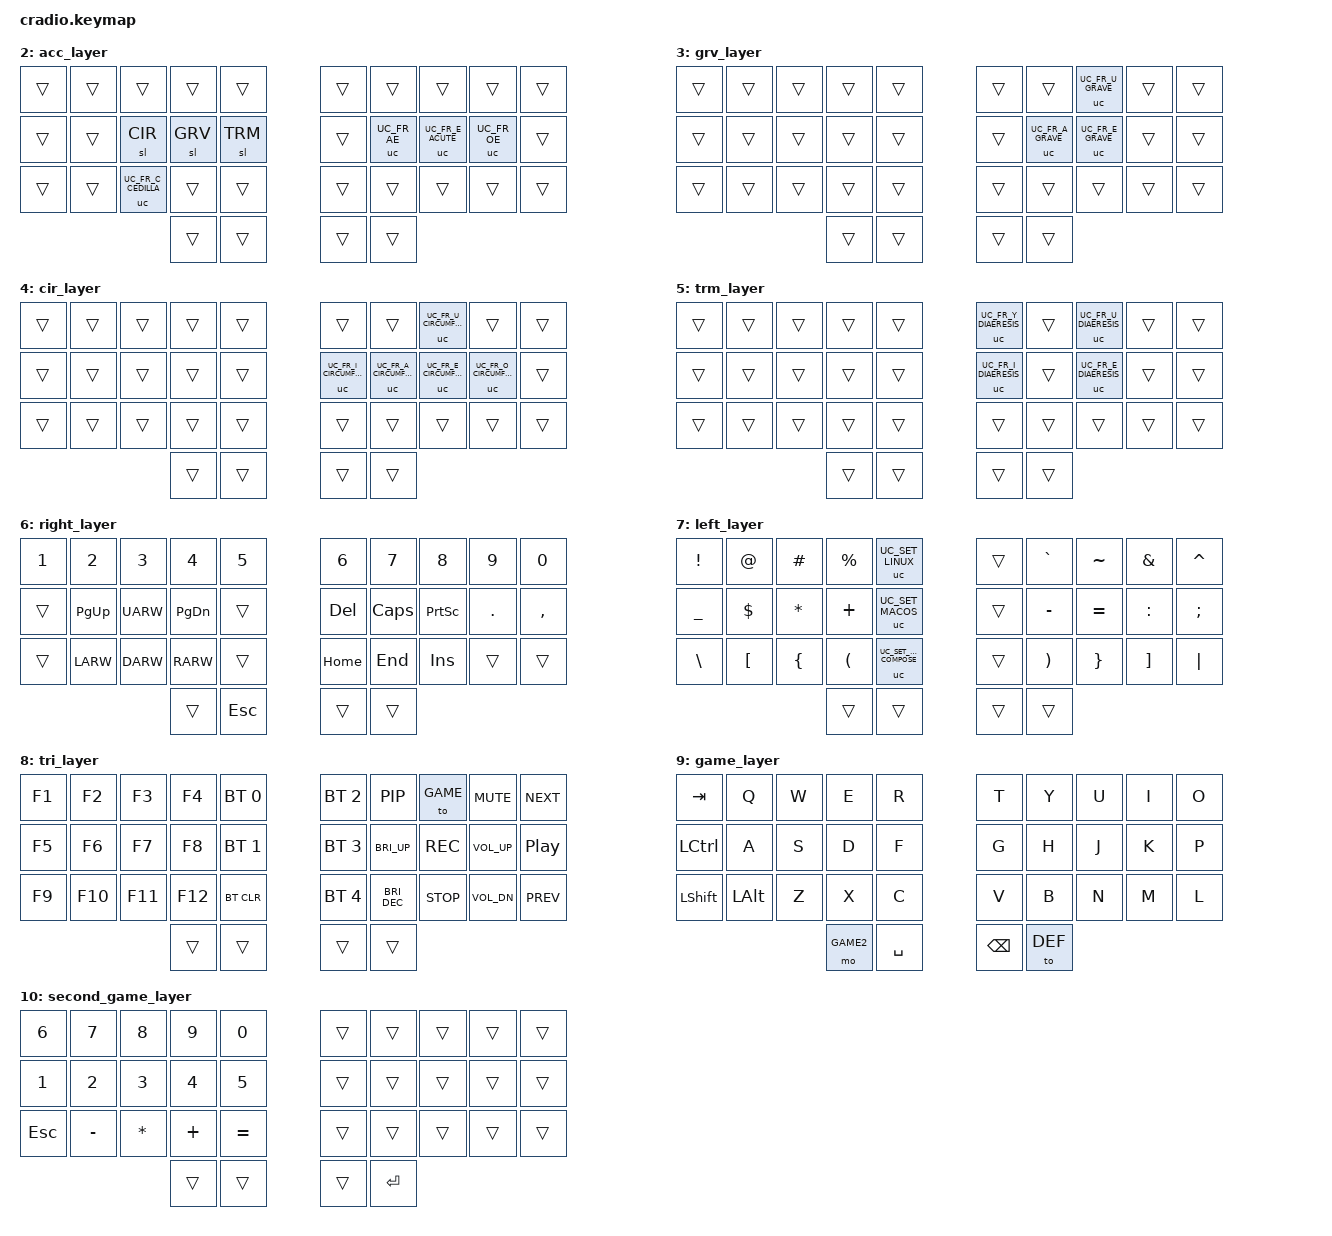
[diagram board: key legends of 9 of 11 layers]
// Copyright (c) 2022 The ZMK Contributors
// SPDX-License-Identifier: MIT

//template
        //╭──────────┬──────────┬──────────┬──────────┬──────────╮   ╭──────────┬──────────┬──────────┬──────────┬──────────╮
        //│          │          │          │          │          │   │          │          │          │          │          │
        // &trans     &trans     &trans     &trans     &trans         &trans     &trans     &trans     &trans      &trans
        //├──────────┼──────────┼──────────┼──────────┼──────────┤   ├──────────┼──────────┼──────────┼──────────┼──────────┤
        //│          │          │          │          │          │   │          │          │          │          │          │
        // &trans     &trans     &trans     &trans     &trans         &trans     &trans     &trans     &trans     &trans
        //├──────────┼──────────┼──────────┼──────────┼──────────┤   ├──────────┼──────────┼──────────┼──────────┼──────────┤
        //│          │          │          │          │          │   │          │          │          │          │          │
        // &trans     &trans     &trans     &trans     &trans         &trans     &trans     &trans     &trans     &trans
        //╰──────────┴──────────┴──────────┼──────────┼──────────┤   ├──────────┼──────────┼──────────┴──────────┴──────────╯
        //                                   &trans     &trans         &trans     &trans
        //                                 ╰──────────┴──────────╯   ╰──────────┴──────────╯

#include <behaviors.dtsi>
#include <dt-bindings/zmk/keys.h>
#include <dt-bindings/zmk/bt.h>
#include <dt-bindings/zmk/modifiers.h>
#include <behaviors/unicode.dtsi>

// Unicode input system. Switch on the fly with &uc UC_SET_* (see left_layer).
&uc {
    default-mode = <UC_MODE_LINUX>;
};

#define HRML(k1,k2,k3,k4) &ht LALT k1  &ht LSHFT k2  &ht LCTRL k3  &ht LGUI k4
#define HRMR(k1,k2,k3,k4) &ht RGUI k1  &ht RCTRL k2  &ht RSHFT k3  &ht RALT k4
#define HRMLU(a,b,c,d) &a LALT 0  &b LSHFT 0  &c LCTRL 0  &d LGUI 0
#define HRMRU(a,b,c,d) &a RGUI 0  &b RCTRL 0  &c RSHFT 0  &d RALT 0

// Layer order matters: a key resolves on the *highest* active layer. The toggled
// language layers must sit below the momentary ones, or holding a thumb would
// leave you stuck in Cyrillic with no numbers, symbols or Shift.
// These indices must match the order of the nodes in the keymap below.
#define DEF   0
#define RU    1
#define ACC   2
#define GRV   3
#define CIR   4
#define TRM   5
#define RIG   6
#define LEF   7
#define TRI   8
#define GAME  9
#define GAME2 10

/ {
    behaviors {
        ht: hold_tap {
            compatible = "zmk,behavior-hold-tap";
            #binding-cells = <2>;
            flavor = "tap-preferred";
            tapping-term-ms = <200>;
            quick-tap-ms = <150>;
            require-prior-idle-ms = <100>;
            bindings = <&kp>, <&kp>;
        };

        // &uc takes two params so it cannot be a hold-tap tap. 0-cell macros
        // plus a dummy second cell is the documented workaround.
        ru_bi_uc: ru_bi_uc { compatible = "zmk,behavior-macro"; #binding-cells = <0>; bindings = <&uc UC_RU_BI>; };
        ru_v_uc:  ru_v_uc  { compatible = "zmk,behavior-macro"; #binding-cells = <0>; bindings = <&uc UC_RU_V>; };
        ru_a_uc:  ru_a_uc  { compatible = "zmk,behavior-macro"; #binding-cells = <0>; bindings = <&uc UC_RU_A>; };
        ru_p_uc:  ru_p_uc  { compatible = "zmk,behavior-macro"; #binding-cells = <0>; bindings = <&uc UC_RU_P>; };
        ru_r_uc:  ru_r_uc  { compatible = "zmk,behavior-macro"; #binding-cells = <0>; bindings = <&uc UC_RU_R>; };
        ru_o_uc:  ru_o_uc  { compatible = "zmk,behavior-macro"; #binding-cells = <0>; bindings = <&uc UC_RU_O>; };
        ru_l_uc:  ru_l_uc  { compatible = "zmk,behavior-macro"; #binding-cells = <0>; bindings = <&uc UC_RU_L>; };
        ru_d_uc:  ru_d_uc  { compatible = "zmk,behavior-macro"; #binding-cells = <0>; bindings = <&uc UC_RU_D>; };

        ru_bi: ru_bi { compatible = "zmk,behavior-hold-tap"; #binding-cells = <2>; flavor = "tap-preferred"; tapping-term-ms = <200>; quick-tap-ms = <150>; require-prior-idle-ms = <100>; bindings = <&kp>, <&ru_bi_uc>; };
        ru_v:  ru_v  { compatible = "zmk,behavior-hold-tap"; #binding-cells = <2>; flavor = "tap-preferred"; tapping-term-ms = <200>; quick-tap-ms = <150>; require-prior-idle-ms = <100>; bindings = <&kp>, <&ru_v_uc>; };
        ru_a:  ru_a  { compatible = "zmk,behavior-hold-tap"; #binding-cells = <2>; flavor = "tap-preferred"; tapping-term-ms = <200>; quick-tap-ms = <150>; require-prior-idle-ms = <100>; bindings = <&kp>, <&ru_a_uc>; };
        ru_p:  ru_p  { compatible = "zmk,behavior-hold-tap"; #binding-cells = <2>; flavor = "tap-preferred"; tapping-term-ms = <200>; quick-tap-ms = <150>; require-prior-idle-ms = <100>; bindings = <&kp>, <&ru_p_uc>; };
        ru_r:  ru_r  { compatible = "zmk,behavior-hold-tap"; #binding-cells = <2>; flavor = "tap-preferred"; tapping-term-ms = <200>; quick-tap-ms = <150>; require-prior-idle-ms = <100>; bindings = <&kp>, <&ru_r_uc>; };
        ru_o:  ru_o  { compatible = "zmk,behavior-hold-tap"; #binding-cells = <2>; flavor = "tap-preferred"; tapping-term-ms = <200>; quick-tap-ms = <150>; require-prior-idle-ms = <100>; bindings = <&kp>, <&ru_o_uc>; };
        ru_l:  ru_l  { compatible = "zmk,behavior-hold-tap"; #binding-cells = <2>; flavor = "tap-preferred"; tapping-term-ms = <200>; quick-tap-ms = <150>; require-prior-idle-ms = <100>; bindings = <&kp>, <&ru_l_uc>; };
        ru_d:  ru_d  { compatible = "zmk,behavior-hold-tap"; #binding-cells = <2>; flavor = "tap-preferred"; tapping-term-ms = <200>; quick-tap-ms = <150>; require-prior-idle-ms = <100>; bindings = <&kp>, <&ru_d_uc>; };
    };

    combos {
        compatible = "zmk,combos";
        combo_acc {
            timeout-ms = <50>;
            require-prior-idle-ms = <100>;
            key-positions = <20 21>;
            bindings = <&sl ACC>;
            layers = <DEF>;
        };
        combo_ru {
            timeout-ms = <50>;
            require-prior-idle-ms = <100>;
            key-positions = <0 1>;
            bindings = <&tog RU>;
            layers = <DEF RU>;
        };
        combo_yo {
            timeout-ms = <50>;
            require-prior-idle-ms = <100>;
            key-positions = <3 4>;
            bindings = <&uc UC_RU_YO>;
            layers = <RU>;
        };
        combo_shch {
            timeout-ms = <50>;
            require-prior-idle-ms = <100>;
            key-positions = <7 8>;
            bindings = <&uc UC_RU_SHCH>;
            layers = <RU>;
        };
        combo_hard {
            timeout-ms = <50>;
            require-prior-idle-ms = <100>;
            key-positions = <26 27>;
            bindings = <&uc UC_RU_HARD>;
            layers = <RU>;
        };
    };

    conditional_layers {
        compatible = "zmk,conditional-layers";
        tri_layer {
            if-layers = <RIG LEF>;
            then-layer = <TRI>;
        };
    };

    keymap {
        compatible = "zmk,keymap";
        default_layer {
            bindings = <
        //╭──────────┬──────────┬──────────┬──────────┬──────────╮   ╭──────────┬──────────┬──────────┬──────────┬──────────╮
        //│  Q       │  G       │  M       │  L       │  W       │   │  Y       │  F       │  U       │  B       │ ' "      │
            &kp Q      &kp G      &kp M      &kp L      &kp W          &kp Y      &kp F      &kp U      &kp B      &kp SQT
        //├──────────┼──────────┼──────────┼──────────┼──────────┤   ├──────────┼──────────┼──────────┼──────────┼──────────┤
        //│  D       │  S       │  T       │  N       │  R       │   │  I       │  A       │  E       │  O       │  H       │
            &kp D      HRML(S,         T,         N,     R)            HRMR(I,     A,         E,         O)         &kp H
        //├──────────┼──────────┼──────────┼──────────┼──────────┤   ├──────────┼──────────┼──────────┼──────────┼──────────┤
        //│  Z       │  X       │  C       │  V       │  J       │   │  K       │  P       │ , <      │ . >      │ / ?      │
            &kp Z      &kp X      &kp C      &kp V      &kp J          &kp K      &kp P      &kp COMMA  &kp DOT    &kp FSLH
        //╰──────────┴──────────┴──────────┼──────────┼──────────┤   ├──────────┼──────────┼──────────┴──────────┴──────────╯
                                           &lt LEF TAB  &kp SPACE      &kp BSPC  &lt RIG ENTER
        //                                 ╰──────────┴──────────╯   ╰──────────┴──────────╯
            >;
        };

        // ЙЦУКЕН. Home-row mods and thumbs match the base layer. ё/щ/ъ are
        // combos: к+е, ш+з, ь+б.
        ru_layer {
            bindings = <
        //╭──────────┬──────────┬──────────┬──────────┬──────────╮   ╭──────────┬──────────┬──────────┬──────────┬──────────╮
        //│  й Й     │  ц Ц     │  у У     │  к К     │  е Е     │   │  н Н     │  г Г     │  ш Ш     │  з З     │  х Х     │
            &uc UC_RU_Y    &uc UC_RU_TS   &uc UC_RU_U    &uc UC_RU_K    &uc UC_RU_YE       &uc UC_RU_N    &uc UC_RU_G    &uc UC_RU_SH    &uc UC_RU_Z    &uc UC_RU_KH
        //├──────────┼──────────┼──────────┼──────────┼──────────┤   ├──────────┼──────────┼──────────┼──────────┼──────────┤
        //│  ф Ф     │  ы Ы     │  в В     │  а А     │  п П     │   │  р Р     │  о О     │  л Л     │  д Д     │  ж Ж     │
            &uc UC_RU_F    HRMLU(ru_bi,    ru_v,        ru_a,          ru_p)              HRMRU(ru_r,    ru_o,        ru_l,           ru_d)          &uc UC_RU_ZH
        //├──────────┼──────────┼──────────┼──────────┼──────────┤   ├──────────┼──────────┼──────────┼──────────┼──────────┤
        //│  я Я     │  ч Ч     │  с С     │  м М     │  и И     │   │  т Т     │  ь Ь     │  б Б     │  ю Ю     │  э Э     │
            &uc UC_RU_YA   &uc UC_RU_CH   &uc UC_RU_S    &uc UC_RU_M    &uc UC_RU_I        &uc UC_RU_T    &uc UC_RU_SOFT &uc UC_RU_B     &uc UC_RU_YU   &uc UC_RU_E
        //╰──────────┴──────────┴──────────┼──────────┼──────────┤   ├──────────┼──────────┼──────────┴──────────┴──────────╯
                                             &trans     &trans         &trans     &trans
        //                                 ╰──────────┴──────────╯   ╰──────────┴──────────╯
            >;
        };

        // Diacritic picker, one-shot via the Z+X combo. Pick the mark, then the
        // letter on its own base position. Glyphs with only one possible mark
        // (é, ç, æ, œ) skip the second step and sit here directly.
        acc_layer {
            bindings = <
        //╭──────────┬──────────┬──────────┬──────────┬──────────╮   ╭──────────┬──────────┬──────────┬──────────┬──────────╮
        //│          │          │          │          │          │   │          │          │          │          │          │
            &trans     &trans     &trans     &trans     &trans         &trans     &trans     &trans     &trans     &trans
        //├──────────┼──────────┼──────────┼──────────┼──────────┤   ├──────────┼──────────┼──────────┼──────────┼──────────┤
        //│          │          │  ^ dead  │  ` dead  │  ¨ dead  │   │          │  æ Æ     │  é É     │  œ Œ     │          │
            &trans     &trans     &sl CIR    &sl GRV    &sl TRM        &trans     &uc UC_FR_AE &uc UC_FR_E_ACUTE &uc UC_FR_OE &trans
        //├──────────┼──────────┼──────────┼──────────┼──────────┤   ├──────────┼──────────┼──────────┼──────────┼──────────┤
        //│          │          │  ç Ç     │          │          │   │          │          │          │          │          │
            &trans     &trans     &uc UC_FR_C_CEDILLA   &trans     &trans         &trans     &trans     &trans     &trans     &trans
        //╰──────────┴──────────┴──────────┼──────────┼──────────┤   ├──────────┼──────────┼──────────┴──────────┴──────────╯
                                             &trans     &trans         &trans     &trans
        //                                 ╰──────────┴──────────╯   ╰──────────┴──────────╯
            >;
        };

        grv_layer {
            bindings = <
        //╭──────────┬──────────┬──────────┬──────────┬──────────╮   ╭──────────┬──────────┬──────────┬──────────┬──────────╮
        //│          │          │          │          │          │   │          │          │  ù Ù     │          │          │
            &trans     &trans     &trans     &trans     &trans         &trans     &trans     &uc UC_FR_U_GRAVE &trans &trans
        //├──────────┼──────────┼──────────┼──────────┼──────────┤   ├──────────┼──────────┼──────────┼──────────┼──────────┤
        //│          │          │          │          │          │   │          │  à À     │  è È     │          │          │
            &trans     &trans     &trans     &trans     &trans         &trans     &uc UC_FR_A_GRAVE &uc UC_FR_E_GRAVE &trans &trans
        //├──────────┼──────────┼──────────┼──────────┼──────────┤   ├──────────┼──────────┼──────────┼──────────┼──────────┤
        //│          │          │          │          │          │   │          │          │          │          │          │
            &trans     &trans     &trans     &trans     &trans         &trans     &trans     &trans     &trans     &trans
        //╰──────────┴──────────┴──────────┼──────────┼──────────┤   ├──────────┼──────────┼──────────┴──────────┴──────────╯
                                             &trans     &trans         &trans     &trans
        //                                 ╰──────────┴──────────╯   ╰──────────┴──────────╯
            >;
        };

        cir_layer {
            bindings = <
        //╭──────────┬──────────┬──────────┬──────────┬──────────╮   ╭──────────┬──────────┬──────────┬──────────┬──────────╮
        //│          │          │          │          │          │   │          │          │  û Û     │          │          │
            &trans     &trans     &trans     &trans     &trans         &trans     &trans     &uc UC_FR_U_CIRCUMFLEX &trans &trans
        //├──────────┼──────────┼──────────┼──────────┼──────────┤   ├──────────┼──────────┼──────────┼──────────┼──────────┤
        //│          │          │          │          │          │   │  î Î     │  â Â     │  ê Ê     │  ô Ô     │          │
            &trans     &trans     &trans     &trans     &trans         &uc UC_FR_I_CIRCUMFLEX &uc UC_FR_A_CIRCUMFLEX &uc UC_FR_E_CIRCUMFLEX &uc UC_FR_O_CIRCUMFLEX &trans
        //├──────────┼──────────┼──────────┼──────────┼──────────┤   ├──────────┼──────────┼──────────┼──────────┼──────────┤
        //│          │          │          │          │          │   │          │          │          │          │          │
            &trans     &trans     &trans     &trans     &trans         &trans     &trans     &trans     &trans     &trans
        //╰──────────┴──────────┴──────────┼──────────┼──────────┤   ├──────────┼──────────┼──────────┴──────────┴──────────╯
                                             &trans     &trans         &trans     &trans
        //                                 ╰──────────┴──────────╯   ╰──────────┴──────────╯
            >;
        };

        trm_layer {
            bindings = <
        //╭──────────┬──────────┬──────────┬──────────┬──────────╮   ╭──────────┬──────────┬──────────┬──────────┬──────────╮
        //│          │          │          │          │          │   │  ÿ Ÿ     │          │  ü Ü     │          │          │
            &trans     &trans     &trans     &trans     &trans         &uc UC_FR_Y_DIAERESIS &trans &uc UC_FR_U_DIAERESIS &trans &trans
        //├──────────┼──────────┼──────────┼──────────┼──────────┤   ├──────────┼──────────┼──────────┼──────────┼──────────┤
        //│          │          │          │          │          │   │  ï Ï     │          │  ë Ë     │          │          │
            &trans     &trans     &trans     &trans     &trans         &uc UC_FR_I_DIAERESIS &trans &uc UC_FR_E_DIAERESIS &trans &trans
        //├──────────┼──────────┼──────────┼──────────┼──────────┤   ├──────────┼──────────┼──────────┼──────────┼──────────┤
        //│          │          │          │          │          │   │          │          │          │          │          │
            &trans     &trans     &trans     &trans     &trans         &trans     &trans     &trans     &trans     &trans
        //╰──────────┴──────────┴──────────┼──────────┼──────────┤   ├──────────┼──────────┼──────────┴──────────┴──────────╯
                                             &trans     &trans         &trans     &trans
        //                                 ╰──────────┴──────────╯   ╰──────────┴──────────╯
            >;
        };

        right_layer {
            bindings = <
        //╭──────────┬──────────┬──────────┬──────────┬──────────╮   ╭──────────┬──────────┬──────────┬──────────┬──────────╮
        //│ 1        │  2       │  3       │  4       │  5       │   │ 6        │ 7        │ 8        │ 9        │   0      │
            &kp N1    &kp N2     &kp N3     &kp N4     &kp N5          &kp N6     &kp N7     &kp N8     &kp N9      &kp N0
        //├──────────┼──────────┼──────────┼──────────┼──────────┤   ├──────────┼──────────┼──────────┼──────────┼──────────┤
        //│          │ PAGE UP  │   UP     │ PAGE DN  │          |   │ DELETE   │ CapsLock │ PrintSc  │ . >      │ , <      |
             &trans   &kp PG_UP   &kp UARW  &kp PG_DN   &trans         &kp DEL   &kp CAPS   &kp PSCRN   &kp DOT   &kp COMMA
        //├──────────┼──────────┼──────────┼──────────┼──────────┤   ├──────────┼──────────┼──────────┼──────────┼──────────┤
        //│          │  LEFT    │ DOWN     │ RIGHT    │          │   │  HOME    │  END     │  INSERT  │          │          │
            &trans    &kp LARW    &kp DARW   &kp RARW    &trans         &kp HOME   &kp END  &kp INS     &trans      &trans
        //╰──────────┴──────────┴──────────┼──────────┼──────────┤   ├──────────┼──────────┼──────────┴──────────┴──────────╯
                                             &trans     &kp ESC        &trans     &trans
        //                                 ╰──────────┴──────────╯   ╰──────────┴──────────╯
            >;
        };

        left_layer {
            bindings = <
        //╭──────────┬──────────┬──────────┬──────────┬──────────╮   ╭──────────┬──────────┬──────────┬──────────┬──────────╮
        //│  !       │  @       │  #       │  %       │ OS:linux │   │          │  `       │  ~       │  &       │  ^       │
            &kp EXCL   &kp AT     &kp HASH   &kp PRCNT &uc UC_SET_LINUX &trans      &kp GRAVE  &kp TILDE  &kp AMPS   &kp CARET
        //├──────────┼──────────┼──────────┼──────────┼──────────┤   ├──────────┼──────────┼──────────┼──────────┼──────────┤
        //│  _       │  $       │  *       │  +       │ OS:mac   │   │          │  -       │  =       │     :    │  ;       │
           &kp UNDER   &kp DLLR   &kp ASTRK &kp PLUS   &uc UC_SET_MACOS &trans     &kp MINUS  &kp EQUAL  &kp COLON   &kp SEMI
        //├──────────┼──────────┼──────────┼──────────┼──────────┤   ├──────────┼──────────┼──────────┼──────────┼──────────┤
        //│    \     │  [       │  {       │  (       │ OS:win   │   │          │  )       │  }       │  ]       │  │       │
           &kp BSLH   &kp LBKT   &kp LBRC   &kp LPAR   &uc UC_SET_WIN_COMPOSE &trans &kp RPAR   &kp RBRC   &kp RBKT &kp PIPE
        //╰──────────┴──────────┴──────────┼──────────┼──────────┤   ├──────────┼──────────┼──────────┴──────────┴──────────╯
                                             &trans     &trans         &trans     &trans
        //                                 ╰──────────┴──────────╯   ╰──────────┴──────────╯
            >;
        };

        tri_layer {
            bindings = <
        //╭──────────┬──────────┬──────────┬───────────┬────────────╮   ╭────────────┬────────────┬──────────┬───────────┬──────────╮
        //│  F1      │  F2      │  F3      │  F4       │ PROFILE 0  │   │ PROFILE 2  │    PIP     │ GAME     │ VOL MUTE  │ NEXTSONG │
            &kp F1     &kp F2     &kp F3     &kp F4     &bt BT_SEL 0     &bt BT_SEL 2  &kp C_PIP    &to GAME   &kp C_MUTE  &kp C_NEXT
        //├──────────┼──────────┼──────────┼───────────┼────────────┤   ├────────────┼────────────┼──────────┼───────────┼──────────┤
        //│  F5      │  F6      │  F7      │  F8       │ PROFILE 1  │   │ PROFILE 3  │ INC BRIGHT │  RECORD  │  VOL UP   │PAUSEMUSIC│
            &kp F5     &kp F6     &kp F7     &kp F8     &bt BT_SEL 1     &bt BT_SEL 3  &kp C_BRI_UP  &kp C_REC  &kp C_VOL_UP &kp C_PP
        //├──────────┼──────────┼──────────┼───────────┼────────────┤   ├────────────┼────────────┼──────────┼───────────┼──────────┤
        //│  F9      │  F10     │  F11     │  F12      │  CLEAR BT  │   │ PROFILE 4  │ DEC BRIGHT │ STOP     │  VOL DOWN │ PREVSONG │
            &kp F9     &kp F10    &kp F11    &kp F12     &bt BT_CLR      &bt BT_SEL 4 &kp C_BRI_DEC &kp C_STOP  &kp C_VOL_DN &kp C_PREV
        //╰──────────┴──────────┴──────────┼───────────┼────────────┤   ├────────────┼────────────┼──────────┴───────────┴──────────╯
                                                &trans     &trans         &trans       &trans
        //                                 ╰───────────┴────────────╯   ╰────────────┴────────────╯
            >;
        };

        game_layer {
            bindings = <
        //╭──────────┬──────────┬──────────┬──────────┬──────────╮   ╭──────────┬──────────┬──────────┬──────────┬──────────╮
        //│   TAB    │  Q       │  W       │  E       │  R       │   │          │          │          │          │          │
            &kp TAB   &kp Q      &kp W      &kp E      &kp R           &kp T       &kp Y      &kp U      &kp I      &kp O
        //├──────────┼──────────┼──────────┼──────────┼──────────┤   ├──────────┼──────────┼──────────┼──────────┼──────────┤
        //│  Ctrl    │ A        │  S       │  D       │  R       │   │          │          │          │          │          │
            &kp LCTRL  &kp A     &kp S      &kp  D      &kp F          &kp G       &kp H      &kp J      &kp K      &kp P
        //├──────────┼──────────┼──────────┼──────────┼──────────┤   ├──────────┼──────────┼──────────┼──────────┼──────────┤
        //│  Shift   │   ALT    │  Z       │  X       │  C       │   │          │          │          │          │          │
            &kp LSHFT  &kp LALT   &kp Z      &kp X      &kp C          &kp V      &kp B       &kp N      &kp M      &kp L
        //╰──────────┴──────────┴──────────┼──────────┼──────────┤   ├──────────┼──────────┼──────────┴──────────┴──────────╯
                                             &mo GAME2  &kp SPACE      &kp BSPC   &to DEF
                                         //╰──────────┴──────────╯   ╰──────────┴──────────╯
            >;
        };

        second_game_layer {
            bindings = <
        //╭──────────┬──────────┬──────────┬──────────┬──────────╮   ╭──────────┬──────────┬──────────┬──────────┬──────────╮
        //│   6      │  7       │  8       │  9       │  0       │   │          │          │          │          │          │
            &kp N6     &kp N7     &kp N8     &kp N9      &kp N0         &trans     &trans    &trans     &trans     &trans
        //├──────────┼──────────┼──────────┼──────────┼──────────┤   ├──────────┼──────────┼──────────┼──────────┼──────────┤
        //│  1       │ 2        │  3       │  4       │  5       │   │          │          │          │          │          │
            &kp N1    &kp N2     &kp N3     &kp N4     &kp N5           &trans     &trans    &trans     &trans     &trans
        //├──────────┼──────────┼──────────┼──────────┼──────────┤   ├──────────┼──────────┼──────────┼──────────┼──────────┤
        //│  ESC     │   -      │    *     │    +     │   =      │   │          │          │          │          │          │
            &kp ESC    &kp MINUS  &kp ASTRK  &kp PLUS  &kp EQUAL        &trans     &trans    &trans     &trans     &trans
        //╰──────────┴──────────┴──────────┼──────────┼──────────┤   ├──────────┼──────────┼──────────┴──────────┴──────────╯
                                              &trans     &trans         &trans    &kp ENTER
                                         //╰──────────┴──────────╯   ╰──────────┴──────────╯
            >;
        };
    };
};
